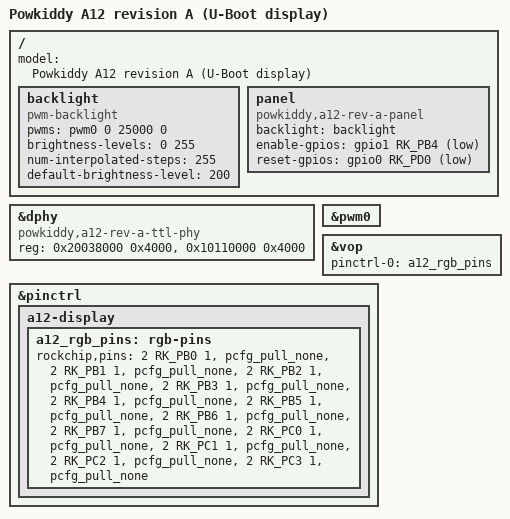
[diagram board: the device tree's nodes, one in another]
// SPDX-License-Identifier: GPL-2.0+
/*
 * A12 revision A with the RGB panel lit in U-Boot (B3 draft, unverified):
 * the normal A12 tree plus the display chain from the ROCKNIX Linux DTS.
 */
#include "rk3128-powkiddy-a12-rev-a.dts"
#include <dt-bindings/pinctrl/rockchip.h>

/ {
	model = "Powkiddy A12 revision A (U-Boot display)";

	backlight: backlight {
		compatible = "pwm-backlight";
		pwms = <&pwm0 0 25000 0>;
		brightness-levels = <0 255>;
		num-interpolated-steps = <255>;
		default-brightness-level = <200>;
	};

	panel {
		compatible = "powkiddy,a12-rev-a-panel";
		backlight = <&backlight>;
		enable-gpios = <&gpio1 RK_PB4 GPIO_ACTIVE_LOW>;
		reset-gpios = <&gpio0 RK_PD0 GPIO_ACTIVE_LOW>;
	};
};

&dphy {
	/* Found by compatible by a12-display.c; no U-Boot PHY driver binds. */
	compatible = "powkiddy,a12-rev-a-ttl-phy";
	reg = <0x20038000 0x4000>, <0x10110000 0x4000>;
};

&pwm0 {
	status = "okay";
};

&vop {
	pinctrl-names = "default";
	pinctrl-0 = <&a12_rgb_pins>;
	status = "okay";
};

&pinctrl {
	a12-display {
		a12_rgb_pins: rgb-pins {
			rockchip,pins = <2 RK_PB0 1 &pcfg_pull_none>, <2 RK_PB1 1 &pcfg_pull_none>,
				<2 RK_PB2 1 &pcfg_pull_none>, <2 RK_PB3 1 &pcfg_pull_none>,
				<2 RK_PB4 1 &pcfg_pull_none>, <2 RK_PB5 1 &pcfg_pull_none>,
				<2 RK_PB6 1 &pcfg_pull_none>, <2 RK_PB7 1 &pcfg_pull_none>,
				<2 RK_PC0 1 &pcfg_pull_none>, <2 RK_PC1 1 &pcfg_pull_none>,
				<2 RK_PC2 1 &pcfg_pull_none>, <2 RK_PC3 1 &pcfg_pull_none>;
		};
	};
};
